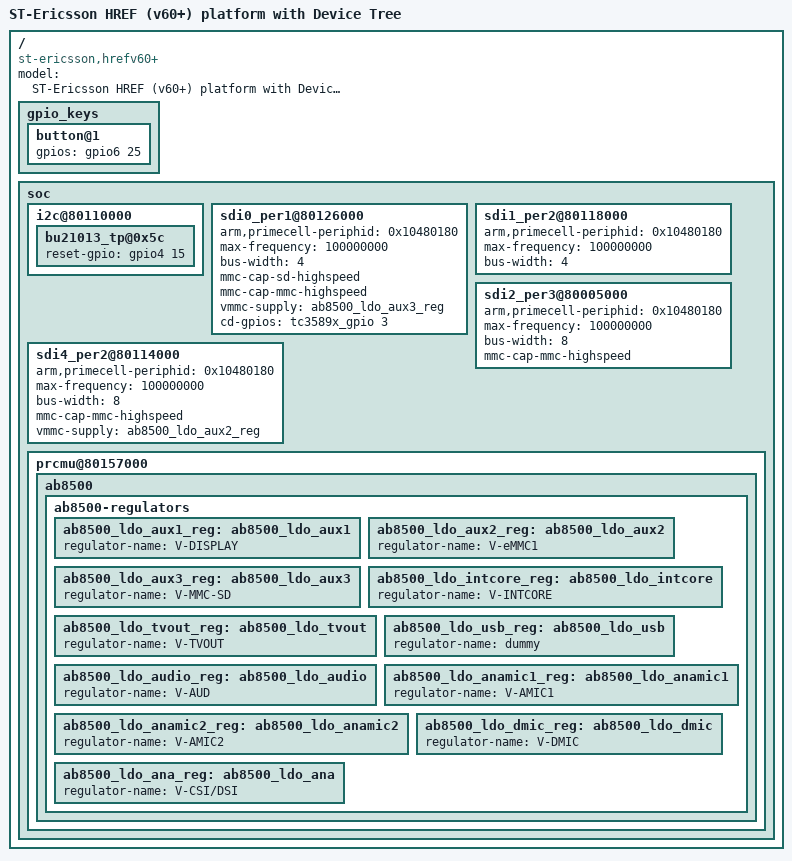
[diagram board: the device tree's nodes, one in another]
/*
 * Copyright 2012 ST-Ericsson AB
 *
 * The code contained herein is licensed under the GNU General Public
 * License. You may obtain a copy of the GNU General Public License
 * Version 2 or later at the following locations:
 *
 * http://www.opensource.org/licenses/gpl-license.html
 * http://www.gnu.org/copyleft/gpl.html
 */

/dts-v1/;
#include "ste-dbx5x0.dtsi"
#include "ste-href.dtsi"
#include "ste-stuib.dtsi"

/ {
	model = "ST-Ericsson HREF (v60+) platform with Device Tree";
	compatible = "st-ericsson,hrefv60+", "st-ericsson,u8500";

	gpio_keys {
		button@1 {
			gpios = <&gpio6 25 0x4>;
		};
	};

	soc {
		i2c@80110000 {
			bu21013_tp@0x5c {
				reset-gpio = <&gpio4 15 0x4>;
			};
		};

		// External Micro SD slot
		sdi0_per1@80126000 {
			arm,primecell-periphid = <0x10480180>;
			max-frequency = <100000000>;
			bus-width = <4>;
			mmc-cap-sd-highspeed;
			mmc-cap-mmc-highspeed;
			vmmc-supply = <&ab8500_ldo_aux3_reg>;

			cd-gpios  = <&tc3589x_gpio 3 0x4>;

			status = "okay";
		};

		// WLAN SDIO channel
		sdi1_per2@80118000 {
			arm,primecell-periphid = <0x10480180>;
			max-frequency = <100000000>;
			bus-width = <4>;

			status = "okay";
		};

		// PoP:ed eMMC
		sdi2_per3@80005000 {
			arm,primecell-periphid = <0x10480180>;
			max-frequency = <100000000>;
			bus-width = <8>;
			mmc-cap-mmc-highspeed;

			status = "okay";
		};

		// On-board eMMC
		sdi4_per2@80114000 {
			arm,primecell-periphid = <0x10480180>;
		        max-frequency = <100000000>;
			bus-width = <8>;
			mmc-cap-mmc-highspeed;
			vmmc-supply = <&ab8500_ldo_aux2_reg>;

			status = "okay";
		};

		prcmu@80157000 {
			ab8500 {
				ab8500-regulators {
					ab8500_ldo_aux1_reg: ab8500_ldo_aux1 {
						regulator-name = "V-DISPLAY";
					};

					ab8500_ldo_aux2_reg: ab8500_ldo_aux2 {
						regulator-name = "V-eMMC1";
					};

					ab8500_ldo_aux3_reg: ab8500_ldo_aux3 {
						regulator-name = "V-MMC-SD";
					};

					ab8500_ldo_intcore_reg: ab8500_ldo_intcore {
						regulator-name = "V-INTCORE";
					};

					ab8500_ldo_tvout_reg: ab8500_ldo_tvout {
						regulator-name = "V-TVOUT";
					};

					ab8500_ldo_usb_reg: ab8500_ldo_usb {
						regulator-name = "dummy";
					};

					ab8500_ldo_audio_reg: ab8500_ldo_audio {
						regulator-name = "V-AUD";
					};

					ab8500_ldo_anamic1_reg: ab8500_ldo_anamic1 {
						regulator-name = "V-AMIC1";
					};

					ab8500_ldo_anamic2_reg: ab8500_ldo_anamic2 {
						regulator-name = "V-AMIC2";
					};

					ab8500_ldo_dmic_reg: ab8500_ldo_dmic {
						regulator-name = "V-DMIC";
					};

					ab8500_ldo_ana_reg: ab8500_ldo_ana {
						regulator-name = "V-CSI/DSI";
					};
				};
			};
		};
	};
};
